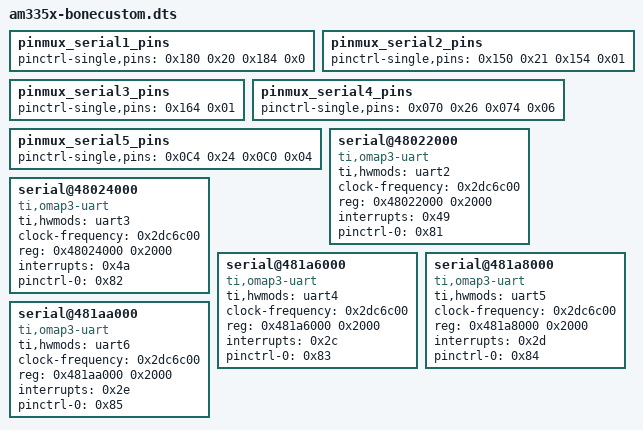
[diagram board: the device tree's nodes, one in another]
/* This line includes the existing Beaglebone Black
Device Tree Source file so portions can be overridden */
#include "am335x-boneblack.dts"
/* This label, am335xx_pinmux, refers to the existing pin muxing
definition found in the am33xx.dtsi include file. */

pinmux_serial1_pins {
    pinctrl-single,pins = <0x180 0x20 0x184 0x0>;
    linux,phandle = <0x81>;
    phandle = <0x81>;
};

pinmux_serial2_pins {
    pinctrl-single,pins = <0x150 0x21 0x154 0x01>;
    linux,phandle = <0x82>;
    phandle = <0x82>;
};
 
pinmux_serial3_pins {
    pinctrl-single,pins = <0x164 0x01>;
    linux,phandle = <0x83>;
    phandle = <0x83>;
};
 
pinmux_serial4_pins {
    pinctrl-single,pins = <0x070 0x26 0x074 0x06>;
    linux,phandle = <0x84>;
    phandle = <0x84>;
};
 
pinmux_serial5_pins {
    pinctrl-single,pins = <0x0C4 0x24 0x0C0 0x04>;
    linux,phandle = <0x85>;
    phandle = <0x85>;
};

serial@48022000 {
    compatible = "ti,omap3-uart";
    ti,hwmods = "uart2";
    clock-frequency = <0x2dc6c00>;
    reg = <0x48022000 0x2000>;
    interrupts = <0x49>;
    pinctrl-names = "default";
    pinctrl-0 = <0x81>;
    status = "okay";
    linux,phandle = <0x19>;
    phandle = <0x19>;
};
 
serial@48024000 {
    compatible = "ti,omap3-uart";
    ti,hwmods = "uart3";
    clock-frequency = <0x2dc6c00>;
    reg = <0x48024000 0x2000>;
    interrupts = <0x4a>;
    pinctrl-names = "default";
    pinctrl-0 = <0x82>;
    status = "okay";
    linux,phandle = <0x1a>;
    phandle = <0x1a>;
};
 
serial@481a6000 {
    compatible = "ti,omap3-uart";
    ti,hwmods = "uart4";
    clock-frequency = <0x2dc6c00>;
    reg = <0x481a6000 0x2000>;
    interrupts = <0x2c>;
    pinctrl-names = "default";
    pinctrl-0 = <0x83>;
    status = "okay";
    linux,phandle = <0x1b>;
    phandle = <0x1b>;
};
 
serial@481a8000 {
    compatible = "ti,omap3-uart";
    ti,hwmods = "uart5";
    clock-frequency = <0x2dc6c00>;
    reg = <0x481a8000 0x2000>;
    interrupts = <0x2d>;
    pinctrl-names = "default";
    pinctrl-0 = <0x84>;
    status = "okay";
    linux,phandle = <0x1c>;
    phandle = <0x1c>;
};
 
serial@481aa000 {
    compatible = "ti,omap3-uart";
    ti,hwmods = "uart6";
    clock-frequency = <0x2dc6c00>;
    reg = <0x481aa000 0x2000>;
    interrupts = <0x2e>;
    pinctrl-names = "default";
    pinctrl-0 = <0x85>;
    status = "okay";
    linux,phandle = <0x1d>;
    phandle = <0x1d>;
};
